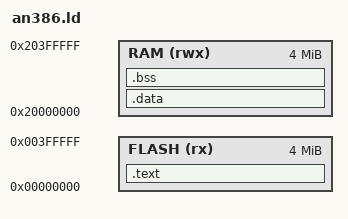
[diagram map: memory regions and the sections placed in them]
/* QEMU mps2-an386 (Cortex-M4): code in SSRAM1, data and stack in SSRAM2/3 */
MEMORY
{
    FLASH (rx)  : ORIGIN = 0x00000000, LENGTH = 4M
    RAM   (rwx) : ORIGIN = 0x20000000, LENGTH = 4M
}

ENTRY(Reset_Handler)

SECTIONS
{
    .text :
    {
        KEEP(*(.vectors))
        *(.text*)
        *(.rodata*)
        . = ALIGN(4);
        _etext = .;
    } > FLASH

    .data : AT(_etext)
    {
        _sdata = .;
        *(.data*)
        . = ALIGN(4);
        _edata = .;
    } > RAM

    .bss (NOLOAD) :
    {
        _sbss = .;
        *(.bss*)
        *(COMMON)
        . = ALIGN(4);
        _ebss = .;
    } > RAM

    _estack = ORIGIN(RAM) + LENGTH(RAM);
}
